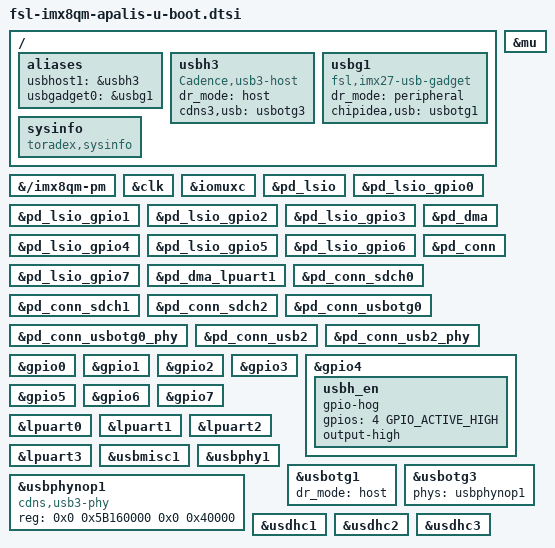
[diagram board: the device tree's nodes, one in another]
// SPDX-License-Identifier: GPL-2.0+ OR X11
/*
 * Copyright 2019 Toradex AG
 */
/ {
	aliases {
		usbhost1 = &usbh3;
		usbgadget0 = &usbg1;
	};

	usbh3: usbh3 {
		compatible = "Cadence,usb3-host";
		dr_mode = "host";
		cdns3,usb = <&usbotg3>;
		status = "okay";
	};

	usbg1: usbg1 {
		compatible = "fsl,imx27-usb-gadget";
		dr_mode = "peripheral";
		chipidea,usb = <&usbotg1>;
		status = "okay";
		bootph-some-ram;
	};
};

&{/imx8qm-pm} {

	bootph-some-ram;
};

/ {
	sysinfo {
		compatible = "toradex,sysinfo";
	};
};

&mu {
	bootph-some-ram;
};

&clk {
	bootph-some-ram;
};

&iomuxc {
	bootph-some-ram;
};

&pd_lsio {
	bootph-some-ram;
};

&pd_lsio_gpio0 {
	bootph-some-ram;
};

&pd_lsio_gpio1 {
	bootph-some-ram;
};

&pd_lsio_gpio2 {
	bootph-some-ram;
};

&pd_lsio_gpio3 {
	bootph-some-ram;
};

&pd_lsio_gpio4 {
	bootph-some-ram;
};

&pd_lsio_gpio5 {
	bootph-some-ram;
};

&pd_lsio_gpio6 {
	bootph-some-ram;
};

&pd_lsio_gpio7 {
	bootph-some-ram;
};

&pd_dma {
	bootph-some-ram;
};

&pd_dma_lpuart1 {
	bootph-some-ram;
};

&pd_conn {
	bootph-some-ram;
};

&pd_conn_sdch0 {
	bootph-some-ram;
};

&pd_conn_sdch1 {
	bootph-some-ram;
};

&pd_conn_sdch2 {
	bootph-some-ram;
};

&pd_conn_usbotg0 {
	bootph-some-ram;
};

&pd_conn_usbotg0_phy {
	bootph-some-ram;
};

&pd_conn_usb2 {
	bootph-some-ram;
};

&pd_conn_usb2_phy {
	bootph-some-ram;
};

&gpio0 {
	bootph-some-ram;
};

&gpio1 {
	bootph-some-ram;
};

&gpio2 {
	bootph-some-ram;
};

&gpio3 {
	bootph-some-ram;
};

&gpio4 {
	bootph-some-ram;

	usbh_en {
		gpio-hog;
		gpios = <4 GPIO_ACTIVE_HIGH>;
		output-high;
	};
};

&gpio5 {
	bootph-some-ram;
};

&gpio6 {
	bootph-some-ram;
};

&gpio7 {
	bootph-some-ram;
};

&lpuart0 {
	bootph-some-ram;
};

&lpuart1 {
	bootph-some-ram;
};

&lpuart2 {
	bootph-some-ram;
};

&lpuart3 {
	bootph-some-ram;
};

/* USB */
&usbmisc1 {
	bootph-some-ram;
};

&usbphy1 {
	bootph-some-ram;
};

&usbotg1 {
	dr_mode = "host";
	bootph-some-ram;
};

&usbphynop1 {
	compatible = "cdns,usb3-phy";
	reg = <0x0 0x5B160000 0x0 0x40000>;
	#phy-cells = <0>;
	bootph-some-ram;
};

&usbotg3 {
	phys = <&usbphynop1>;
	bootph-some-ram;
};

&usdhc1 {
	bootph-some-ram;
};

&usdhc2 {
	bootph-some-ram;
};

&usdhc3 {
	bootph-some-ram;
};
